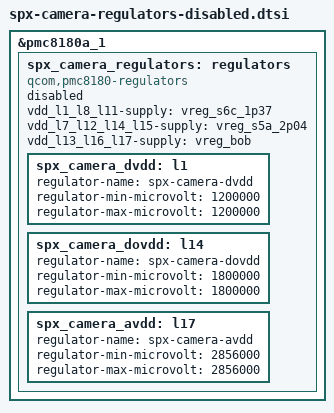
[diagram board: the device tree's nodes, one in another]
// SPDX-License-Identifier: GPL-2.0-only
/* Offline provider review. No camera or rail is enabled by this source. */
&pmc8180a_1 {
	spx_camera_regulators: regulators {
		compatible = "qcom,pmc8180-regulators";
		status = "disabled";

		/* Same upstream wiring as the board's existing PMIC A RPMh node. */
		vdd_l1_l8_l11-supply = <&vreg_s6c_1p37>;
		vdd_l7_l12_l14_l15-supply = <&vreg_s5a_2p04>;
		vdd_l13_l16_l17-supply = <&vreg_bob>;

		spx_camera_dvdd: l1 {
			regulator-name = "spx-camera-dvdd";
			regulator-min-microvolt = <1200000>;
			regulator-max-microvolt = <1200000>;
		};

		spx_camera_dovdd: l14 {
			regulator-name = "spx-camera-dovdd";
			regulator-min-microvolt = <1800000>;
			regulator-max-microvolt = <1800000>;
		};

		spx_camera_avdd: l17 {
			regulator-name = "spx-camera-avdd";
			/* Actual programmed code 0x0b28; 2.850 V is not an 8 mV step. */
			regulator-min-microvolt = <2856000>;
			regulator-max-microvolt = <2856000>;
		};
	};
};
